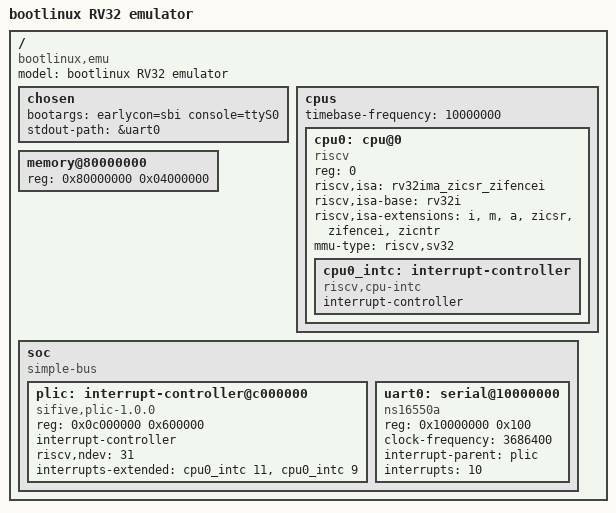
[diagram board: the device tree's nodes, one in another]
// Device tree for the bootlinux emulator. Tells Linux what hardware exists:
// one RV32IMA hart with Sv32, 64 MiB of RAM, a PLIC and a 16550 UART.
/dts-v1/;

/ {
	#address-cells = <1>;
	#size-cells = <1>;
	compatible = "bootlinux,emu";
	model = "bootlinux RV32 emulator";

	chosen {
		bootargs = "earlycon=sbi console=ttyS0";
		stdout-path = &uart0;
	};

	cpus {
		#address-cells = <1>;
		#size-cells = <0>;
		timebase-frequency = <10000000>;   // must match TIMEBASE_HZ

		cpu0: cpu@0 {
			device_type = "cpu";
			reg = <0>;
			status = "okay";
			compatible = "riscv";
			riscv,isa = "rv32ima_zicsr_zifencei";
			riscv,isa-base = "rv32i";
			riscv,isa-extensions = "i", "m", "a", "zicsr", "zifencei", "zicntr";
			mmu-type = "riscv,sv32";

			cpu0_intc: interrupt-controller {
				#interrupt-cells = <1>;
				interrupt-controller;
				compatible = "riscv,cpu-intc";
			};
		};
	};

	memory@80000000 {
		device_type = "memory";
		reg = <0x80000000 0x04000000>;     // 64 MiB, must match --ram
	};

	soc {
		#address-cells = <1>;
		#size-cells = <1>;
		compatible = "simple-bus";
		ranges;

		plic: interrupt-controller@c000000 {
			compatible = "sifive,plic-1.0.0";
			reg = <0x0c000000 0x600000>;
			#address-cells = <0>;
			#interrupt-cells = <1>;
			interrupt-controller;
			riscv,ndev = <31>;
			// context 0 = M-mode external, context 1 = S-mode external
			interrupts-extended = <&cpu0_intc 11>, <&cpu0_intc 9>;
		};

		uart0: serial@10000000 {
			compatible = "ns16550a";
			reg = <0x10000000 0x100>;
			clock-frequency = <3686400>;
			interrupt-parent = <&plic>;
			interrupts = <10>;
		};
	};
};
